# ATmega2564RFR2 register map
Vendor: Atmel; File version: 1.0
CPU: other r0p0, little endian, no MPU, no FPU, 4 interrupt priority bits
Registers are 8-bit, read-write, reset 0x0 unless marked. A register's access mark holds for its fields unless they carry their own. Offsets are from the block's base; [hi:lo] are bit positions; 'fields as' and 'values as' point back to an identical list.

## TC2 — Timer/Counter, 8-bit Async
Base 0x00000037
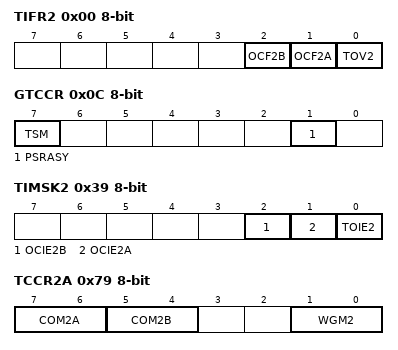
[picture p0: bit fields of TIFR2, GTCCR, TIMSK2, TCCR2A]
0x00 TIFR2 — Timer/Counter Interrupt Flag Register
  [2] OCF2B — Output Compare Flag 2 B
  [1] OCF2A — Output Compare Flag 2 A
  [0] TOV2 — Timer/Counter2 Overflow Flag
0x0C GTCCR — General Timer Counter Control register
  [7] TSM — Timer/Counter Synchronization Mode
  [1] PSRASY — Prescaler Reset Timer/Counter2
0x39 TIMSK2 — Timer/Counter Interrupt Mask register
  [2] OCIE2B — Timer/Counter2 Output Compare Match B Interrupt Enable
  [1] OCIE2A — Timer/Counter2 Output Compare Match A Interrupt Enable
  [0] TOIE2 — Timer/Counter2 Overflow Interrupt Enable
0x79 TCCR2A — Timer/Counter2 Control Register A
  [7:6] COM2A — Compare Match Output A Mode
    0=Normal port operation, OC2A disconnected; 1=Toggle OC2A on Compare Match; 2=Clear OC2A on Compare Match; 3=Set OC2A on Compare Match
  [5:4] COM2B — Compare Match Output B Mode
    0=Normal port operation, OC2B disconnected; 1=Toggle OC2B on Compare Match; 2=Clear OC2B on Compare Match; 3=Set OC2B on Compare Match
  [1:0] WGM2 — Waveform Generation Mode
    0=Normal mode of operation; 1=PWM, phase correct, TOP=0xFF; 2=CTC, TOP = OCRA; 3=Fast PWM, TOP=0xFF
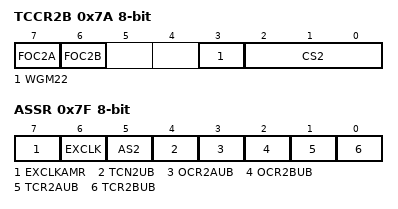
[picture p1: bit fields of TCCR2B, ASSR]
0x7A TCCR2B — Timer/Counter2 Control Register B
  [7] FOC2A — Force Output Compare A
  [6] FOC2B — Force Output Compare B
  [3] WGM22 — Waveform Generation Mode
  [2:0] CS2 — Clock Select
    0=No clock source (Timer/Counter2 stopped); 1=clk_T2S/1 (no prescaling); 2=clk_T2S/8 (from prescaler); 3=clk_T2S/32 (from prescaler); 4=clk_T2S/64 (from prescaler); 5=clk_T2S/128 (from prescaler); 6=clk_T2S/256 (from prescaler); 7=clk_T2S/1024 (from prescaler)
0x7B TCNT2 — Timer/Counter2
0x7C OCR2A — Timer/Counter2 Output Compare Register A
0x7D OCR2B — Timer/Counter2 Output Compare Register B
0x7F ASSR — Asynchronous Status Register
  [7] EXCLKAMR — Enable External Clock Input for AMR
  [6] EXCLK — Enable External Clock Input
  [5] AS2 — Timer/Counter2 Asynchronous Mode
  [4] TCN2UB — Timer/Counter2 Update Busy
  [3] OCR2AUB — Timer/Counter2 Output Compare Register A Update Busy
  [2] OCR2BUB — Timer/Counter2 Output Compare Register B Update Busy
  [1] TCR2AUB — Timer/Counter2 Control Register A Update Busy
  [0] TCR2BUB — Timer/Counter2 Control Register B Update Busy

## TC3 — Timer/Counter, 16-bit
Base 0x00000038
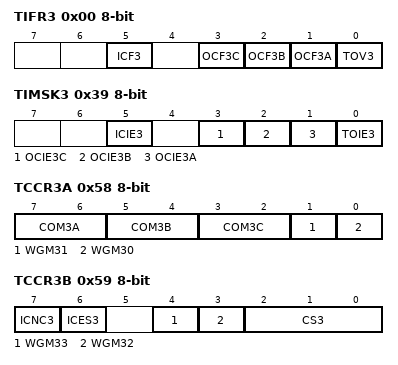
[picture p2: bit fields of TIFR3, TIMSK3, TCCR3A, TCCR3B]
0x00 TIFR3 — Timer/Counter3 Interrupt Flag Register
  [5] ICF3 — Timer/Counter3 Input Capture Flag
  [3] OCF3C — Timer/Counter3 Output Compare C Match Flag
  [2] OCF3B — Timer/Counter3 Output Compare B Match Flag
  [1] OCF3A — Timer/Counter3 Output Compare A Match Flag
  [0] TOV3 — Timer/Counter3 Overflow Flag
0x39 TIMSK3 — Timer/Counter3 Interrupt Mask Register
  [5] ICIE3 — Timer/Counter3 Input Capture Interrupt Enable
  [3] OCIE3C — Timer/Counter3 Output Compare C Match Interrupt Enable
  [2] OCIE3B — Timer/Counter3 Output Compare B Match Interrupt Enable
  [1] OCIE3A — Timer/Counter3 Output Compare A Match Interrupt Enable
  [0] TOIE3 — Timer/Counter3 Overflow Interrupt Enable
0x58 TCCR3A — Timer/Counter3 Control Register A
  [7:6] COM3A — Compare Output Mode for Channel A
    0=Normal port operation, OCnA/OCnB/OCnC disconnected; 1=Toggle OCnA/OCnB/OCnC on Compare Match; 2=Clear OCnA/OCnB/OCnC on Compare Match (set output to low level); 3=Set OCnA/OCnB/OCnC on Compare Match (set output to high level)
  [5:4] COM3B — Compare Output Mode for Channel B
    values as COM3A
  [3:2] COM3C — Compare Output Mode for Channel C
    values as COM3A
  [1] WGM31 — Waveform Generation Mode
  [0] WGM30 — Waveform Generation Mode
0x59 TCCR3B — Timer/Counter3 Control Register B
  [7] ICNC3 — Input Capture 3 Noise Canceller
  [6] ICES3 — Input Capture 3 Edge Select
  [4] WGM33 — Waveform Generation Mode
  [3] WGM32 — Waveform Generation Mode
  [2:0] CS3 — Clock Select
    0=No clock source (Timer/Counter stopped); 1=clk_IO/1 (no prescaling); 2=clk_IO/8 (from prescaler); 3=clk_IO/64 (from prescaler); 4=clk_IO/256 (from prescaler); 5=clk_IO/1024 (from prescaler); 6=External clock source on Tn pin, clock on falling edge; 7=External clock source on Tn pin, clock on rising edge
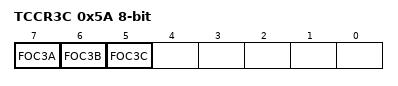
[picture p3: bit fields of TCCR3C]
0x5A TCCR3C — Timer/Counter3 Control Register C
  [7] FOC3A — Force Output Compare for Channel A
  [6] FOC3B — Force Output Compare for Channel B
  [5] FOC3C — Force Output Compare for Channel C
0x5C TCNT3 16-bit (reset mask 0xFF) — Timer/Counter3 Bytes
0x5E ICR3 16-bit (reset mask 0xFF) — Timer/Counter3 Input Capture Register Bytes
0x60 OCR3A 16-bit (reset mask 0xFF) — Timer/Counter3 Output Compare Register A Bytes
0x62 OCR3B 16-bit (reset mask 0xFF) — Timer/Counter3 Output Compare Register B Bytes
0x64 OCR3C 16-bit (reset mask 0xFF) — Timer/Counter3 Output Compare Register C Bytes
